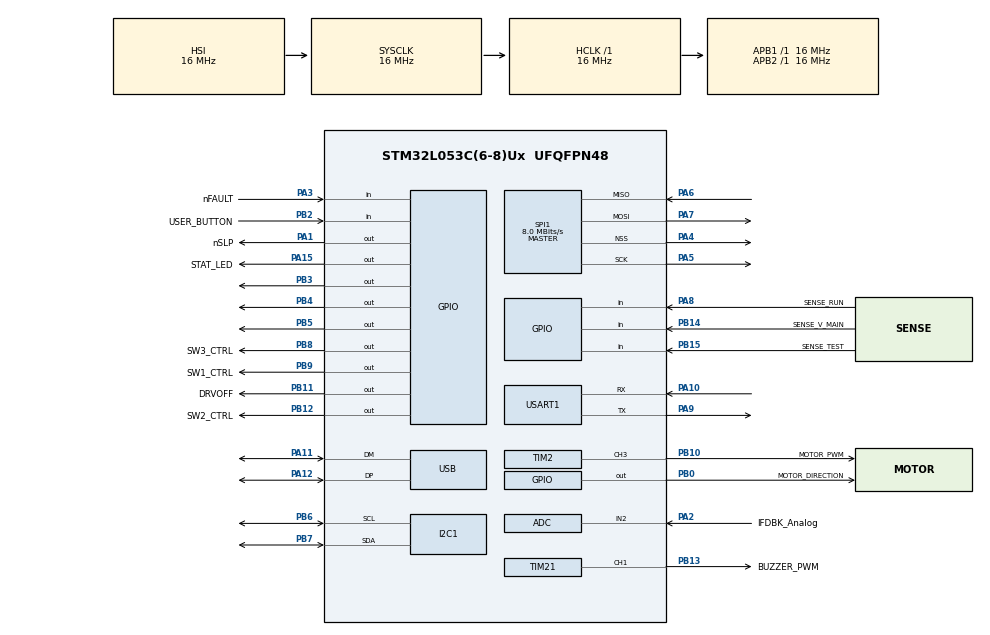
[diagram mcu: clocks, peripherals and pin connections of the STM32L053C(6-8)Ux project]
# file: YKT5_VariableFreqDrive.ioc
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I2C1.Timing=0x00503D58
Mcu.Family=STM32L0
Mcu.Name=STM32L053C(6-8)Ux
Mcu.Package=UFQFPN48
NVIC.USB_IRQn=true\:0\:0\:false\:false\:true\:false\:true\:true
PA1.GPIO_Label=nSLP
PA1.Signal=GPIO_Output
PA10.Mode=Asynchronous
PA10.Signal=USART1_RX
PA11.Mode=Device
PA11.Signal=USB_DM
PA12.Mode=Device
PA12.Signal=USB_DP
PA13.Mode=Serial_Wire
PA13.Signal=SYS_SWDIO
PA14.Mode=Serial_Wire
PA14.Signal=SYS_SWCLK
PA15.GPIO_Label=STAT_LED
PA15.Signal=GPIO_Output
PA2.GPIO_Label=IFDBK_Analog
PA2.Mode=IN2
PA2.Signal=ADC_IN2
PA3.GPIO_Label=nFAULT
PA3.GPIO_PuPd=GPIO_PULLUP
PA3.Signal=GPIO_Input
PA4.Mode=NSS_Signal_Hard_Output
PA4.Signal=SPI1_NSS
PA5.Mode=Full_Duplex_Master
PA5.Signal=SPI1_SCK
PA6.Mode=Full_Duplex_Master
PA6.Signal=SPI1_MISO
PA7.Mode=Full_Duplex_Master
PA7.Signal=SPI1_MOSI
PA8.GPIO_Label=SENSE_RUN
PA8.Signal=GPIO_Input
PA9.Mode=Asynchronous
PA9.Signal=USART1_TX
PB0.GPIO_Label=MOTOR_DIRECTION
PB0.Signal=GPIO_Output
PB10.GPIO_Label=MOTOR_PWM
PB10.Signal=S_TIM2_CH3
PB11.GPIO_Label=DRVOFF
PB11.Signal=GPIO_Output
PB12.GPIO_Label=SW2_CTRL
PB12.Signal=GPIO_Output
PB13.GPIO_Label=BUZZER_PWM
PB13.Signal=S_TIM21_CH1
PB14.GPIO_Label=SENSE_V_MAIN
PB14.Signal=GPIO_Input
PB15.GPIO_Label=SENSE_TEST
PB15.Signal=GPIO_Input
PB2.GPIO_Label=USER_BUTTON
PB2.Signal=GPIO_Input
PB3.Signal=GPIO_Output
PB4.Signal=GPIO_Output
PB5.Signal=GPIO_Output
PB6.Mode=I2C
PB6.Signal=I2C1_SCL
PB7.Mode=I2C
PB7.Signal=I2C1_SDA
PB8.GPIO_Label=SW3_CTRL
PB8.Signal=GPIO_Output
PB9.GPIO_Label=SW1_CTRL
PB9.Signal=GPIO_Output
ProjectManager.HeapSize=0x200
ProjectManager.StackSize=0x400
ProjectManager.TargetToolchain=STM32CubeIDE
RCC.AHBFreq_Value=16000000
RCC.APB1Freq_Value=16000000
RCC.APB1TimFreq_Value=16000000
RCC.APB2Freq_Value=16000000
RCC.APB2TimFreq_Value=16000000
RCC.HCLKFreq_Value=16000000
RCC.HSE_VALUE=8000000
RCC.HSI16_VALUE=16000000
RCC.HSI48MClockSelection=RCC_USBCLKSOURCE_HSI48
RCC.HSI48_VALUE=48000000
RCC.HSI_VALUE=16000000
RCC.LSE_VALUE=32768
RCC.MSI_VALUE=2097000
RCC.SYSCLKFreq_VALUE=16000000
RCC.SYSCLKSource=RCC_SYSCLKSOURCE_HSI
RCC.VCOOutputFreq_Value=48000000
SH.S_TIM21_CH1.0=TIM21_CH1,PWM Generation1 CH1
SH.S_TIM2_CH3.0=TIM2_CH3,PWM Generation3 CH3
SPI1.BaudRatePrescaler=SPI_BAUDRATEPRESCALER_2
SPI1.CalculateBaudRate=8.0 MBits/s
SPI1.Direction=SPI_DIRECTION_2LINES
SPI1.Mode=SPI_MODE_MASTER
SPI1.VirtualNSS=VM_NSSHARD
SPI1.VirtualType=VM_MASTER
TIM2.Channel-PWM\ Generation3\ CH3=TIM_CHANNEL_3
TIM2.Pulse-PWM\ Generation3\ CH3=32768
TIM21.Channel-PWM\ Generation1\ CH1=TIM_CHANNEL_1
TIM21.Pulse-PWM\ Generation1\ CH1=32768
USART1.VirtualMode-Asynchronous=VM_ASYNC
USB_DEVICE.CLASS_NAME_FS=CDC
USB_DEVICE.PRODUCT_STRING_CDC_FS=VariableFrequencyDrive
USB_DEVICE.VirtualMode=Cdc
USB_DEVICE.VirtualModeFS=Cdc_FS
VP_TIM21_VS_ClockSourceINT.Mode=Internal
VP_USB_DEVICE_VS_USB_DEVICE_CDC_FS.Mode=CDC_FS
board=custom

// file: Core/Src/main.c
/* USER CODE BEGIN Header */
/**
  ******************************************************************************
  * @file           : main.c
  * @brief          : Main program body
  ******************************************************************************
  * @attention
  *
  * Copyright (c) 2025 STMicroelectronics.
  * All rights reserved.
  *
  * This software is licensed under terms that can be found in the LICENSE file
  * in the root directory of this software component.
  * If no LICENSE file comes with this software, it is provided AS-IS.
  *
  ******************************************************************************
  */
/* USER CODE END Header */
extern "C"{
	#include "../Inc/main.h"
	#include "usb_device.h"
}

ADC_HandleTypeDef hadc;

I2C_HandleTypeDef hi2c1;

SPI_HandleTypeDef hspi1;

TIM_HandleTypeDef htim2;
TIM_HandleTypeDef htim21;

UART_HandleTypeDef huart1;

void SystemClock_Config(void);
static void MX_GPIO_Init(void);
static void MX_ADC_Init(void);
static void MX_I2C1_Init(void);
static void MX_SPI1_Init(void);
static void MX_TIM2_Init(void);
static void MX_TIM21_Init(void);
static void MX_USART1_UART_Init(void);

int main(void)
{

  /* MCU Configuration--------------------------------------------------------*/

  /* Reset of all peripherals, Initializes the Flash interface and the Systick. */
  HAL_Init();

  /* Configure the system clock */
  SystemClock_Config();

  /* Initialize all configured peripherals */
  MX_GPIO_Init();
  MX_ADC_Init();
  MX_I2C1_Init();
  MX_SPI1_Init();
  MX_TIM2_Init();
  MX_TIM21_Init();
  MX_USART1_UART_Init();
  MX_USB_DEVICE_Init();

  /* Infinite loop */
  /* USER CODE BEGIN WHILE */
  while (1)
  {

	  HAL_GPIO_WritePin(SW1_CTRL_GPIO_Port, SW1_CTRL_Pin, 1);
	  HAL_Delay(1000);
	  HAL_GPIO_WritePin(SW2_CTRL_GPIO_Port, SW2_CTRL_Pin, 1);
	  HAL_Delay(1000);
	  HAL_GPIO_WritePin(SW3_CTRL_GPIO_Port, SW3_CTRL_Pin, 1);
	  HAL_Delay(1000);
	  HAL_GPIO_WritePin(SW1_CTRL_GPIO_Port, SW1_CTRL_Pin, 0);
	  HAL_Delay(1000);
	  HAL_GPIO_WritePin(SW2_CTRL_GPIO_Port, SW2_CTRL_Pin, 0);
	  HAL_Delay(1000);
	  HAL_GPIO_WritePin(SW3_CTRL_GPIO_Port, SW3_CTRL_Pin, 0);
	  HAL_Delay(1000);
    /* USER CODE END WHILE */

  }
}

void SystemClock_Config(void)
{
  RCC_OscInitTypeDef RCC_OscInitStruct = {0};
  RCC_ClkInitTypeDef RCC_ClkInitStruct = {0};
  RCC_PeriphCLKInitTypeDef PeriphClkInit = {0};

  /** Configure the main internal regulator output voltage
  */
  __HAL_PWR_VOLTAGESCALING_CONFIG(PWR_REGULATOR_VOLTAGE_SCALE1);

  /** Initializes the RCC Oscillators according to the specified parameters
  * in the RCC_OscInitTypeDef structure.
  */
  RCC_OscInitStruct.OscillatorType = RCC_OSCILLATORTYPE_HSI|RCC_OSCILLATORTYPE_HSI48;
  RCC_OscInitStruct.HSIState = RCC_HSI_ON;
  RCC_OscInitStruct.HSICalibrationValue = RCC_HSICALIBRATION_DEFAULT;
  RCC_OscInitStruct.HSI48State = RCC_HSI48_ON;
  RCC_OscInitStruct.PLL.PLLState = RCC_PLL_NONE;
  if (HAL_RCC_OscConfig(&RCC_OscInitStruct) != HAL_OK)
  {
    Error_Handler();
  }

  /** Initializes the CPU, AHB and APB buses clocks
  */
  RCC_ClkInitStruct.ClockType = RCC_CLOCKTYPE_HCLK|RCC_CLOCKTYPE_SYSCLK
                              |RCC_CLOCKTYPE_PCLK1|RCC_CLOCKTYPE_PCLK2;
  RCC_ClkInitStruct.SYSCLKSource = RCC_SYSCLKSOURCE_HSI;
  RCC_ClkInitStruct.AHBCLKDivider = RCC_SYSCLK_DIV1;
  RCC_ClkInitStruct.APB1CLKDivider = RCC_HCLK_DIV1;
  RCC_ClkInitStruct.APB2CLKDivider = RCC_HCLK_DIV1;

  if (HAL_RCC_ClockConfig(&RCC_ClkInitStruct, FLASH_LATENCY_0) != HAL_OK)
  {
    Error_Handler();
  }
  PeriphClkInit.PeriphClockSelection = RCC_PERIPHCLK_USART1|RCC_PERIPHCLK_I2C1
                              |RCC_PERIPHCLK_USB;
  PeriphClkInit.Usart1ClockSelection = RCC_USART1CLKSOURCE_PCLK2;
  PeriphClkInit.I2c1ClockSelection = RCC_I2C1CLKSOURCE_PCLK1;
  PeriphClkInit.UsbClockSelection = RCC_USBCLKSOURCE_HSI48;
  if (HAL_RCCEx_PeriphCLKConfig(&PeriphClkInit) != HAL_OK)
  {
    Error_Handler();
  }
}

static void MX_ADC_Init(void)
{

  ADC_ChannelConfTypeDef sConfig = {0};

  /** Configure the global features of the ADC (Clock, Resolution, Data Alignment and number of conversion)
  */
  hadc.Instance = ADC1;
  hadc.Init.OversamplingMode = DISABLE;
  hadc.Init.ClockPrescaler = ADC_CLOCK_SYNC_PCLK_DIV1;
  hadc.Init.Resolution = ADC_RESOLUTION_12B;
  hadc.Init.SamplingTime = ADC_SAMPLETIME_1CYCLE_5;
  hadc.Init.ScanConvMode = ADC_SCAN_DIRECTION_FORWARD;
  hadc.Init.DataAlign = ADC_DATAALIGN_RIGHT;
  hadc.Init.ContinuousConvMode = DISABLE;
  hadc.Init.DiscontinuousConvMode = DISABLE;
  hadc.Init.ExternalTrigConvEdge = ADC_EXTERNALTRIGCONVEDGE_NONE;
  hadc.Init.ExternalTrigConv = ADC_SOFTWARE_START;
  hadc.Init.DMAContinuousRequests = DISABLE;
  hadc.Init.EOCSelection = ADC_EOC_SINGLE_CONV;
  hadc.Init.Overrun = ADC_OVR_DATA_PRESERVED;
  hadc.Init.LowPowerAutoWait = DISABLE;
  hadc.Init.LowPowerFrequencyMode = DISABLE;
  hadc.Init.LowPowerAutoPowerOff = DISABLE;
  if (HAL_ADC_Init(&hadc) != HAL_OK)
  {
    Error_Handler();
  }

  /** Configure for the selected ADC regular channel to be converted.
  */
  sConfig.Channel = ADC_CHANNEL_2;
  sConfig.Rank = ADC_RANK_CHANNEL_NUMBER;
  if (HAL_ADC_ConfigChannel(&hadc, &sConfig) != HAL_OK)
  {
    Error_Handler();
  }

}

static void MX_I2C1_Init(void)
{

  hi2c1.Instance = I2C1;
  hi2c1.Init.Timing = 0x00503D58;
  hi2c1.Init.OwnAddress1 = 0;
  hi2c1.Init.AddressingMode = I2C_ADDRESSINGMODE_7BIT;
  hi2c1.Init.DualAddressMode = I2C_DUALADDRESS_DISABLE;
  hi2c1.Init.OwnAddress2 = 0;
  hi2c1.Init.OwnAddress2Masks = I2C_OA2_NOMASK;
  hi2c1.Init.GeneralCallMode = I2C_GENERALCALL_DISABLE;
  hi2c1.Init.NoStretchMode = I2C_NOSTRETCH_DISABLE;
  if (HAL_I2C_Init(&hi2c1) != HAL_OK)
  {
    Error_Handler();
  }

  /** Configure Analogue filter
  */
  if (HAL_I2CEx_ConfigAnalogFilter(&hi2c1, I2C_ANALOGFILTER_ENABLE) != HAL_OK)
  {
    Error_Handler();
  }

  /** Configure Digital filter
  */
  if (HAL_I2CEx_ConfigDigitalFilter(&hi2c1, 0) != HAL_OK)
  {
    Error_Handler();
  }

}

static void MX_SPI1_Init(void)
{

  /* SPI1 parameter configuration*/
  hspi1.Instance = SPI1;
  hspi1.Init.Mode = SPI_MODE_MASTER;
  hspi1.Init.Direction = SPI_DIRECTION_2LINES;
  hspi1.Init.DataSize = SPI_DATASIZE_8BIT;
  hspi1.Init.CLKPolarity = SPI_POLARITY_LOW;
  hspi1.Init.CLKPhase = SPI_PHASE_1EDGE;
  hspi1.Init.NSS = SPI_NSS_HARD_OUTPUT;
  hspi1.Init.BaudRatePrescaler = SPI_BAUDRATEPRESCALER_2;
  hspi1.Init.FirstBit = SPI_FIRSTBIT_MSB;
  hspi1.Init.TIMode = SPI_TIMODE_DISABLE;
  hspi1.Init.CRCCalculation = SPI_CRCCALCULATION_DISABLE;
  hspi1.Init.CRCPolynomial = 7;
  if (HAL_SPI_Init(&hspi1) != HAL_OK)
  {
    Error_Handler();
  }

}

static void MX_TIM2_Init(void)
{

  TIM_MasterConfigTypeDef sMasterConfig = {0};
  TIM_OC_InitTypeDef sConfigOC = {0};

  htim2.Instance = TIM2;
  htim2.Init.Prescaler = 0;
  htim2.Init.CounterMode = TIM_COUNTERMODE_UP;
  htim2.Init.Period = 65535;
  htim2.Init.ClockDivision = TIM_CLOCKDIVISION_DIV1;
  htim2.Init.AutoReloadPreload = TIM_AUTORELOAD_PRELOAD_DISABLE;
  if (HAL_TIM_PWM_Init(&htim2) != HAL_OK)
  {
    Error_Handler();
  }
  sMasterConfig.MasterOutputTrigger = TIM_TRGO_RESET;
  sMasterConfig.MasterSlaveMode = TIM_MASTERSLAVEMODE_DISABLE;
  if (HAL_TIMEx_MasterConfigSynchronization(&htim2, &sMasterConfig) != HAL_OK)
  {
    Error_Handler();
  }
  sConfigOC.OCMode = TIM_OCMODE_PWM1;
  sConfigOC.Pulse = 32768;
  sConfigOC.OCPolarity = TIM_OCPOLARITY_HIGH;
  sConfigOC.OCFastMode = TIM_OCFAST_DISABLE;
  if (HAL_TIM_PWM_ConfigChannel(&htim2, &sConfigOC, TIM_CHANNEL_3) != HAL_OK)
  {
    Error_Handler();
  }
  HAL_TIM_MspPostInit(&htim2);

}

static void MX_TIM21_Init(void)
{

  TIM_ClockConfigTypeDef sClockSourceConfig = {0};
  TIM_MasterConfigTypeDef sMasterConfig = {0};
  TIM_OC_InitTypeDef sConfigOC = {0};

  htim21.Instance = TIM21;
  htim21.Init.Prescaler = 0;
  htim21.Init.CounterMode = TIM_COUNTERMODE_UP;
  htim21.Init.Period = 65535;
  htim21.Init.ClockDivision = TIM_CLOCKDIVISION_DIV1;
  htim21.Init.AutoReloadPreload = TIM_AUTORELOAD_PRELOAD_DISABLE;
  if (HAL_TIM_Base_Init(&htim21) != HAL_OK)
  {
    Error_Handler();
  }
  sClockSourceConfig.ClockSource = TIM_CLOCKSOURCE_INTERNAL;
  if (HAL_TIM_ConfigClockSource(&htim21, &sClockSourceConfig) != HAL_OK)
  {
    Error_Handler();
  }
  if (HAL_TIM_PWM_Init(&htim21) != HAL_OK)
  {
    Error_Handler();
  }
  sMasterConfig.MasterOutputTrigger = TIM_TRGO_RESET;
  sMasterConfig.MasterSlaveMode = TIM_MASTERSLAVEMODE_DISABLE;
  if (HAL_TIMEx_MasterConfigSynchronization(&htim21, &sMasterConfig) != HAL_OK)
  {
    Error_Handler();
  }
  sConfigOC.OCMode = TIM_OCMODE_PWM1;
  sConfigOC.Pulse = 32768;
  sConfigOC.OCPolarity = TIM_OCPOLARITY_HIGH;
  sConfigOC.OCFastMode = TIM_OCFAST_DISABLE;
  if (HAL_TIM_PWM_ConfigChannel(&htim21, &sConfigOC, TIM_CHANNEL_1) != HAL_OK)
  {
    Error_Handler();
  }
  HAL_TIM_MspPostInit(&htim21);

}

static void MX_USART1_UART_Init(void)
{

  huart1.Instance = USART1;
  huart1.Init.BaudRate = 115200;
  huart1.Init.WordLength = UART_WORDLENGTH_8B;
  huart1.Init.StopBits = UART_STOPBITS_1;
  huart1.Init.Parity = UART_PARITY_NONE;
  huart1.Init.Mode = UART_MODE_TX_RX;
  huart1.Init.HwFlowCtl = UART_HWCONTROL_NONE;
  huart1.Init.OverSampling = UART_OVERSAMPLING_16;
  huart1.Init.OneBitSampling = UART_ONE_BIT_SAMPLE_DISABLE;
  huart1.AdvancedInit.AdvFeatureInit = UART_ADVFEATURE_NO_INIT;
  if (HAL_UART_Init(&huart1) != HAL_OK)
  {
    Error_Handler();
  }

}

static void MX_GPIO_Init(void)
{
  GPIO_InitTypeDef GPIO_InitStruct = {0};

  /* GPIO Ports Clock Enable */
  __HAL_RCC_GPIOA_CLK_ENABLE();
  __HAL_RCC_GPIOB_CLK_ENABLE();

  /*Configure GPIO pin Output Level */
  HAL_GPIO_WritePin(GPIOA, nSLP_Pin|STAT_LED_Pin, GPIO_PIN_RESET);

  /*Configure GPIO pin Output Level */
  HAL_GPIO_WritePin(GPIOB, MOTOR_DIRECTION_Pin|DRVOFF_Pin|SW2_CTRL_Pin|GPIO_PIN_3
                          |GPIO_PIN_4|GPIO_PIN_5|SW3_CTRL_Pin|SW1_CTRL_Pin, GPIO_PIN_RESET);

  /*Configure GPIO pins : nSLP_Pin STAT_LED_Pin */
  GPIO_InitStruct.Pin = nSLP_Pin|STAT_LED_Pin;
  GPIO_InitStruct.Mode = GPIO_MODE_OUTPUT_PP;
  GPIO_InitStruct.Pull = GPIO_NOPULL;
  GPIO_InitStruct.Speed = GPIO_SPEED_FREQ_LOW;
  HAL_GPIO_Init(GPIOA, &GPIO_InitStruct);

  /*Configure GPIO pin : nFAULT_Pin */
  GPIO_InitStruct.Pin = nFAULT_Pin;
  GPIO_InitStruct.Mode = GPIO_MODE_INPUT;
  GPIO_InitStruct.Pull = GPIO_PULLUP;
  HAL_GPIO_Init(nFAULT_GPIO_Port, &GPIO_InitStruct);

  /*Configure GPIO pins : MOTOR_DIRECTION_Pin DRVOFF_Pin SW2_CTRL_Pin PB3
                           PB4 PB5 SW3_CTRL_Pin SW1_CTRL_Pin */
  GPIO_InitStruct.Pin = MOTOR_DIRECTION_Pin|DRVOFF_Pin|SW2_CTRL_Pin|GPIO_PIN_3
                          |GPIO_PIN_4|GPIO_PIN_5|SW3_CTRL_Pin|SW1_CTRL_Pin;
  GPIO_InitStruct.Mode = GPIO_MODE_OUTPUT_PP;
  GPIO_InitStruct.Pull = GPIO_NOPULL;
  GPIO_InitStruct.Speed = GPIO_SPEED_FREQ_LOW;
  HAL_GPIO_Init(GPIOB, &GPIO_InitStruct);

  /*Configure GPIO pins : USER_BUTTON_Pin SENSE_V_MAIN_Pin SENSE_TEST_Pin */
  GPIO_InitStruct.Pin = USER_BUTTON_Pin|SENSE_V_MAIN_Pin|SENSE_TEST_Pin;
  GPIO_InitStruct.Mode = GPIO_MODE_INPUT;
  GPIO_InitStruct.Pull = GPIO_NOPULL;
  HAL_GPIO_Init(GPIOB, &GPIO_InitStruct);

  /*Configure GPIO pin : SENSE_RUN_Pin */
  GPIO_InitStruct.Pin = SENSE_RUN_Pin;
  GPIO_InitStruct.Mode = GPIO_MODE_INPUT;
  GPIO_InitStruct.Pull = GPIO_NOPULL;
  HAL_GPIO_Init(SENSE_RUN_GPIO_Port, &GPIO_InitStruct);

}

void Error_Handler(void)
{
  __disable_irq();
  while (1)
  {
  }
}
